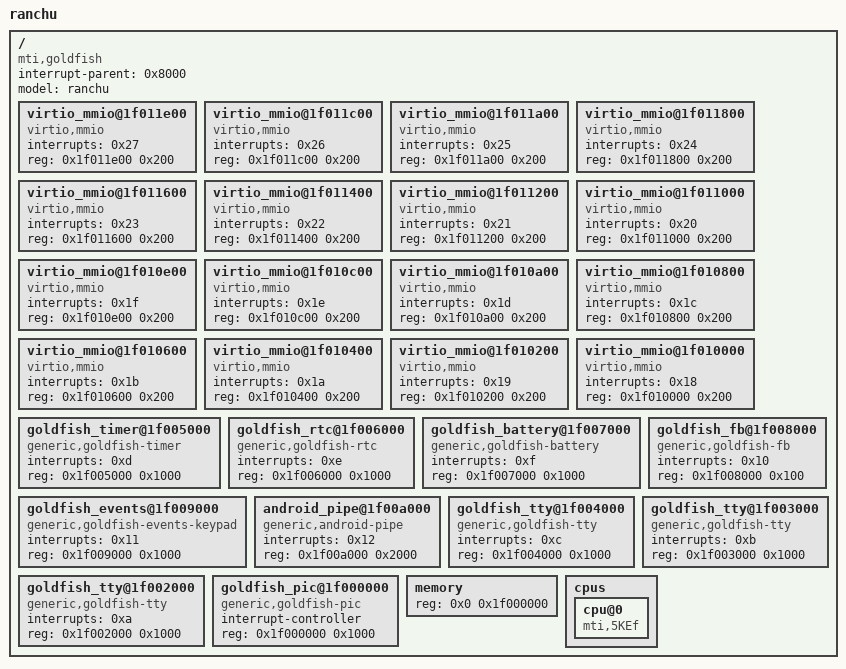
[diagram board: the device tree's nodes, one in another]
/dts-v1/;

/ {
	interrupt-parent = <0x8000>;
	#size-cells = <0x1>;
	#address-cells = <0x1>;
	compatible = "mti,goldfish";
        model = "ranchu";

	virtio_mmio@1f011e00 {
		interrupts = <0x27>;
		reg = <0x1f011e00 0x200>;
		compatible = "virtio,mmio";
	};

	virtio_mmio@1f011c00 {
		interrupts = <0x26>;
		reg = <0x1f011c00 0x200>;
		compatible = "virtio,mmio";
	};

	virtio_mmio@1f011a00 {
		interrupts = <0x25>;
		reg = <0x1f011a00 0x200>;
		compatible = "virtio,mmio";
	};

	virtio_mmio@1f011800 {
		interrupts = <0x24>;
		reg = <0x1f011800 0x200>;
		compatible = "virtio,mmio";
	};

	virtio_mmio@1f011600 {
		interrupts = <0x23>;
		reg = <0x1f011600 0x200>;
		compatible = "virtio,mmio";
	};

	virtio_mmio@1f011400 {
		interrupts = <0x22>;
		reg = <0x1f011400 0x200>;
		compatible = "virtio,mmio";
	};

	virtio_mmio@1f011200 {
		interrupts = <0x21>;
		reg = <0x1f011200 0x200>;
		compatible = "virtio,mmio";
	};

	virtio_mmio@1f011000 {
		interrupts = <0x20>;
		reg = <0x1f011000 0x200>;
		compatible = "virtio,mmio";
	};

	virtio_mmio@1f010e00 {
		interrupts = <0x1f>;
		reg = <0x1f010e00 0x200>;
		compatible = "virtio,mmio";
	};

	virtio_mmio@1f010c00 {
		interrupts = <0x1e>;
		reg = <0x1f010c00 0x200>;
		compatible = "virtio,mmio";
	};

	virtio_mmio@1f010a00 {
		interrupts = <0x1d>;
		reg = <0x1f010a00 0x200>;
		compatible = "virtio,mmio";
	};

	virtio_mmio@1f010800 {
		interrupts = <0x1c>;
		reg = <0x1f010800 0x200>;
		compatible = "virtio,mmio";
	};

	virtio_mmio@1f010600 {
		interrupts = <0x1b>;
		reg = <0x1f010600 0x200>;
		compatible = "virtio,mmio";
	};

	virtio_mmio@1f010400 {
		interrupts = <0x1a>;
		reg = <0x1f010400 0x200>;
		compatible = "virtio,mmio";
	};

	virtio_mmio@1f010200 {
		interrupts = <0x19>;
		reg = <0x1f010200 0x200>;
		compatible = "virtio,mmio";
	};

	virtio_mmio@1f010000 {
		interrupts = <0x18>;
		reg = <0x1f010000 0x200>;
		compatible = "virtio,mmio";
	};

	goldfish_timer@1f005000 {
		interrupts = <0xd>;
		reg = <0x1f005000 0x1000>;
		compatible = "generic,goldfish-timer";
	};

	goldfish_rtc@1f006000 {
		interrupts = <0xe>;
		reg = <0x1f006000 0x1000>;
		compatible = "generic,goldfish-rtc";
	};

	goldfish_battery@1f007000 {
		interrupts = <0xf>;
		reg = <0x1f007000 0x1000>;
		compatible = "generic,goldfish-battery";
	};

	goldfish_fb@1f008000 {
		interrupts = <0x10>;
		reg = <0x1f008000 0x100>;
		compatible = "generic,goldfish-fb";
	};

	goldfish_events@1f009000 {
		interrupts = <0x11>;
		reg = <0x1f009000 0x1000>;
		compatible = "generic,goldfish-events-keypad";
	};

	android_pipe@1f00a000 {
		interrupts = <0x12>;
		reg = <0x1f00a000 0x2000>;
		compatible = "generic,android-pipe";
	};

	goldfish_tty@1f004000 {
		interrupts = <0xc>;
		reg = <0x1f004000 0x1000>;
		compatible = "generic,goldfish-tty";
	};

	goldfish_tty@1f003000 {
		interrupts = <0xb>;
		reg = <0x1f003000 0x1000>;
		compatible = "generic,goldfish-tty";
	};

	goldfish_tty@1f002000 {
		interrupts = <0xa>;
		reg = <0x1f002000 0x1000>;
		compatible = "generic,goldfish-tty";
	};

	goldfish_pic@1f000000 {
		#interrupt-cells = <0x1>;
		phandle = <0x8000>;
		interrupt-controller;
		reg = <0x1f000000 0x1000>;
		compatible = "generic,goldfish-pic";
	};

	memory {
		reg = <0x0 0x1f000000>;
		device_type = "memory";
	};

	cpus {

		cpu@0 {
			compatible = "mti,5KEf";
			device_type = "cpu";
		};
	};
};
